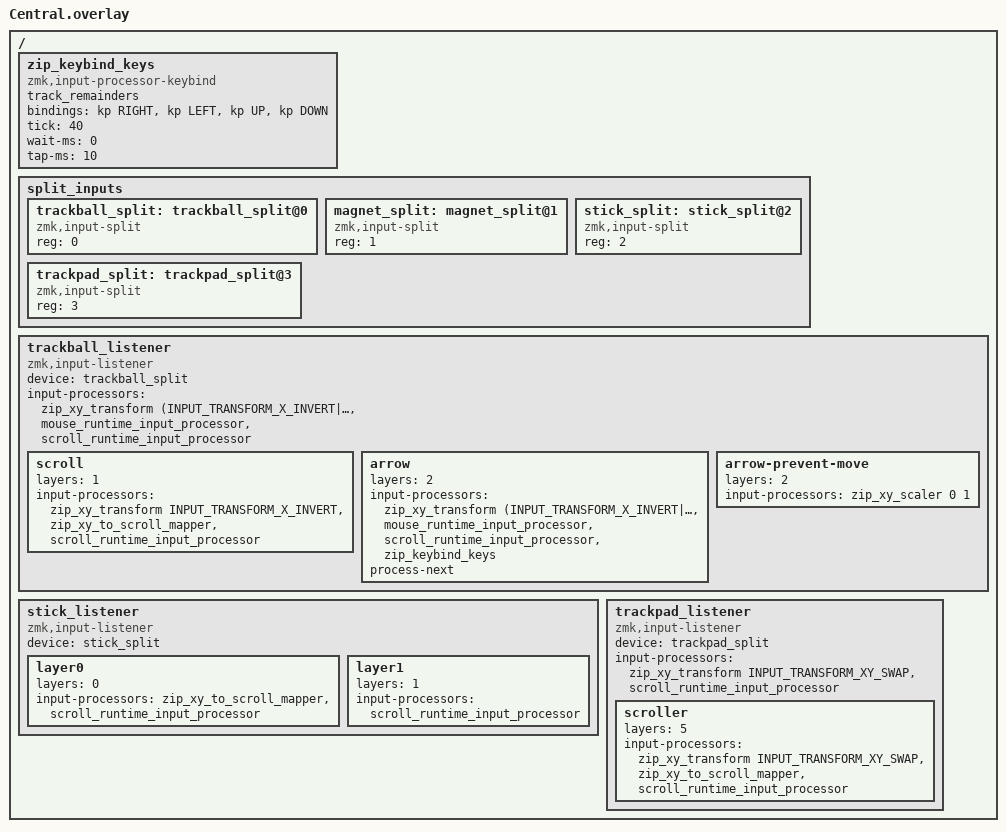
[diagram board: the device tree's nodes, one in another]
#include <input/processors/runtime-input-processor.dtsi>

/ {
    zip_keybind_keys: zip_keybind_keys {
        compatible = "zmk,input-processor-keybind";
        #input-processor-cells = <0>;
        track_remainders;
        bindings = <&kp RIGHT>,
                   <&kp LEFT>,
                   <&kp UP>,
                   <&kp DOWN>;
        tick = <40>;
        wait-ms = <0>;
        tap-ms = <10>;
    };

    split_inputs {
        #address-cells = <1>;
        #size-cells = <0>;

        trackball_split: trackball_split@0 {
            compatible = "zmk,input-split";
            reg = <0>;
        };

        magnet_split: magnet_split@1 {
            compatible = "zmk,input-split";
            reg = <1>;
        };

        stick_split: stick_split@2 {
            compatible = "zmk,input-split";
            reg = <2>;
        };

        trackpad_split: trackpad_split@3 {
            compatible = "zmk,input-split";
            reg = <3>;
        };
    };

    trackball_listener: trackball_listener {
        compatible = "zmk,input-listener";
        status = "okay";
        device = <&trackball_split>;
        input-processors = <&zip_xy_transform (INPUT_TRANSFORM_X_INVERT|INPUT_TRANSFORM_Y_INVERT)>,
                           <&mouse_runtime_input_processor &scroll_runtime_input_processor>;

        scroll {
            layers = <1>;
            input-processors = <&zip_xy_transform INPUT_TRANSFORM_X_INVERT>,
                               <&zip_xy_to_scroll_mapper>,
                               <&scroll_runtime_input_processor>;
        };

        arrow {
            layers = <2>;
            input-processors = <&zip_xy_transform (INPUT_TRANSFORM_X_INVERT|INPUT_TRANSFORM_Y_INVERT)>,
                               <&mouse_runtime_input_processor &scroll_runtime_input_processor>,
                               <&zip_keybind_keys>;
            process-next;
        };

        arrow-prevent-move {
            layers = <2>;
            input-processors = <&zip_xy_scaler 0 1>;
        };
    };

    stick_listener: stick_listener {
        compatible = "zmk,input-listener";
        status = "okay";
        device = <&stick_split>;

        layer0 {
            layers = <0>;
            input-processors = <&zip_xy_to_scroll_mapper>,
                               <&scroll_runtime_input_processor>;
        };

        layer1 {
            layers = <1>;
            input-processors = <&scroll_runtime_input_processor>;
        };
    };

    trackpad_listener: trackpad_listener {
        compatible = "zmk,input-listener";
        status = "okay";
        device = <&trackpad_split>;
        input-processors = <&zip_xy_transform INPUT_TRANSFORM_XY_SWAP>,
                           <&scroll_runtime_input_processor>;

        scroller {
            layers = <5>;
            input-processors = <&zip_xy_transform INPUT_TRANSFORM_XY_SWAP>,
                               <&zip_xy_to_scroll_mapper>,
                               <&scroll_runtime_input_processor>;
        };
    };
};
